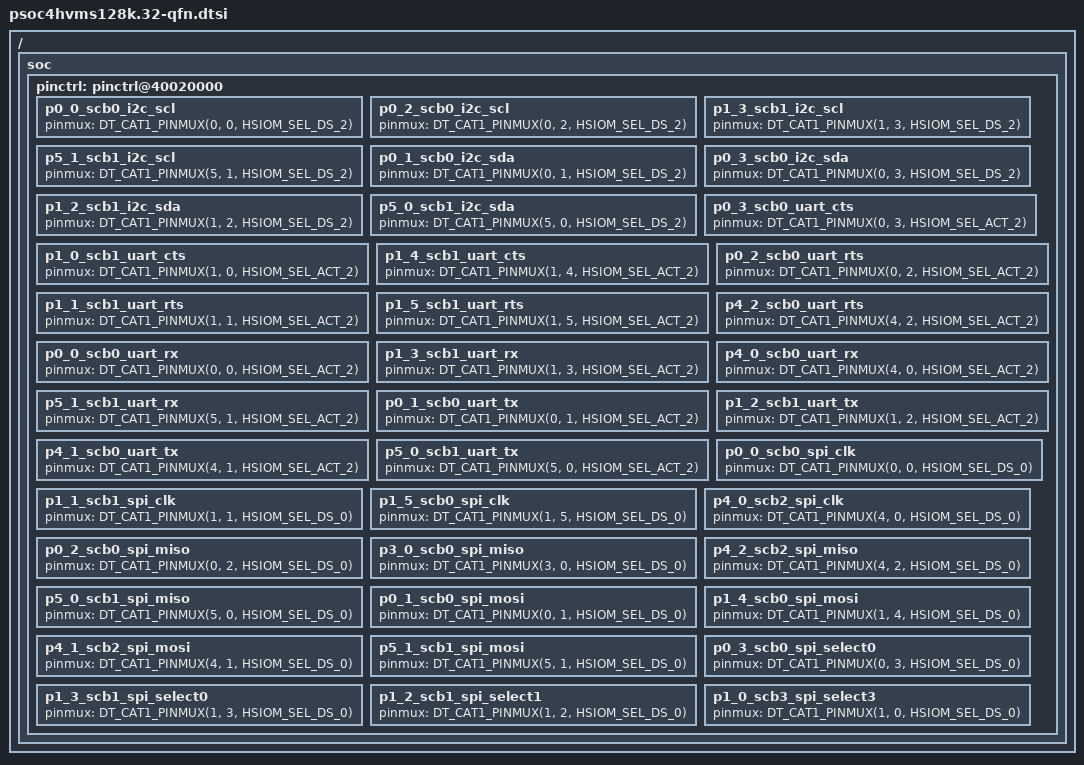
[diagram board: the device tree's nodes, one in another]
/*
 * SPDX-FileCopyrightText: Copyright (c) 2026 Infineon Technologies AG,
 * SPDX-FileCopyrightText: or an affiliate of Infineon Technologies AG. All rights reserved.
 *
 * SPDX-License-Identifier: Apache-2.0
 */

#include <zephyr/dt-bindings/gpio/gpio.h>
#include <zephyr/dt-bindings/pinctrl/ifx_cat1-pinctrl.h>
#include "psoc4hvms128k.dtsi"

/ {
	soc {
		pinctrl: pinctrl@40020000 {
			/* scb_i2c_scl */
			/omit-if-no-ref/ p0_0_scb0_i2c_scl: p0_0_scb0_i2c_scl {
				pinmux = <DT_CAT1_PINMUX(0, 0, HSIOM_SEL_DS_2)>;
			};

			/omit-if-no-ref/ p0_2_scb0_i2c_scl: p0_2_scb0_i2c_scl {
				pinmux = <DT_CAT1_PINMUX(0, 2, HSIOM_SEL_DS_2)>;
			};

			/omit-if-no-ref/ p1_3_scb1_i2c_scl: p1_3_scb1_i2c_scl {
				pinmux = <DT_CAT1_PINMUX(1, 3, HSIOM_SEL_DS_2)>;
			};

			/omit-if-no-ref/ p5_1_scb1_i2c_scl: p5_1_scb1_i2c_scl {
				pinmux = <DT_CAT1_PINMUX(5, 1, HSIOM_SEL_DS_2)>;
			};

			/* scb_i2c_sda */
			/omit-if-no-ref/ p0_1_scb0_i2c_sda: p0_1_scb0_i2c_sda {
				pinmux = <DT_CAT1_PINMUX(0, 1, HSIOM_SEL_DS_2)>;
			};

			/omit-if-no-ref/ p0_3_scb0_i2c_sda: p0_3_scb0_i2c_sda {
				pinmux = <DT_CAT1_PINMUX(0, 3, HSIOM_SEL_DS_2)>;
			};

			/omit-if-no-ref/ p1_2_scb1_i2c_sda: p1_2_scb1_i2c_sda {
				pinmux = <DT_CAT1_PINMUX(1, 2, HSIOM_SEL_DS_2)>;
			};

			/omit-if-no-ref/ p5_0_scb1_i2c_sda: p5_0_scb1_i2c_sda {
				pinmux = <DT_CAT1_PINMUX(5, 0, HSIOM_SEL_DS_2)>;
			};

			/* scb_uart_cts */
			/omit-if-no-ref/ p0_3_scb0_uart_cts: p0_3_scb0_uart_cts {
				pinmux = <DT_CAT1_PINMUX(0, 3, HSIOM_SEL_ACT_2)>;
			};

			/omit-if-no-ref/ p1_0_scb1_uart_cts: p1_0_scb1_uart_cts {
				pinmux = <DT_CAT1_PINMUX(1, 0, HSIOM_SEL_ACT_2)>;
			};

			/omit-if-no-ref/ p1_4_scb1_uart_cts: p1_4_scb1_uart_cts {
				pinmux = <DT_CAT1_PINMUX(1, 4, HSIOM_SEL_ACT_2)>;
			};

			/* scb_uart_rts */
			/omit-if-no-ref/ p0_2_scb0_uart_rts: p0_2_scb0_uart_rts {
				pinmux = <DT_CAT1_PINMUX(0, 2, HSIOM_SEL_ACT_2)>;
			};

			/omit-if-no-ref/ p1_1_scb1_uart_rts: p1_1_scb1_uart_rts {
				pinmux = <DT_CAT1_PINMUX(1, 1, HSIOM_SEL_ACT_2)>;
			};

			/omit-if-no-ref/ p1_5_scb1_uart_rts: p1_5_scb1_uart_rts {
				pinmux = <DT_CAT1_PINMUX(1, 5, HSIOM_SEL_ACT_2)>;
			};

			/omit-if-no-ref/ p4_2_scb0_uart_rts: p4_2_scb0_uart_rts {
				pinmux = <DT_CAT1_PINMUX(4, 2, HSIOM_SEL_ACT_2)>;
			};

			/* scb_uart_rx */
			/omit-if-no-ref/ p0_0_scb0_uart_rx: p0_0_scb0_uart_rx {
				pinmux = <DT_CAT1_PINMUX(0, 0, HSIOM_SEL_ACT_2)>;
			};

			/omit-if-no-ref/ p1_3_scb1_uart_rx: p1_3_scb1_uart_rx {
				pinmux = <DT_CAT1_PINMUX(1, 3, HSIOM_SEL_ACT_2)>;
			};

			/omit-if-no-ref/ p4_0_scb0_uart_rx: p4_0_scb0_uart_rx {
				pinmux = <DT_CAT1_PINMUX(4, 0, HSIOM_SEL_ACT_2)>;
			};

			/omit-if-no-ref/ p5_1_scb1_uart_rx: p5_1_scb1_uart_rx {
				pinmux = <DT_CAT1_PINMUX(5, 1, HSIOM_SEL_ACT_2)>;
			};

			/* scb_uart_tx */
			/omit-if-no-ref/ p0_1_scb0_uart_tx: p0_1_scb0_uart_tx {
				pinmux = <DT_CAT1_PINMUX(0, 1, HSIOM_SEL_ACT_2)>;
			};

			/omit-if-no-ref/ p1_2_scb1_uart_tx: p1_2_scb1_uart_tx {
				pinmux = <DT_CAT1_PINMUX(1, 2, HSIOM_SEL_ACT_2)>;
			};

			/omit-if-no-ref/ p4_1_scb0_uart_tx: p4_1_scb0_uart_tx {
				pinmux = <DT_CAT1_PINMUX(4, 1, HSIOM_SEL_ACT_2)>;
			};

			/omit-if-no-ref/ p5_0_scb1_uart_tx: p5_0_scb1_uart_tx {
				pinmux = <DT_CAT1_PINMUX(5, 0, HSIOM_SEL_ACT_2)>;
			};

			/* scb_spi_clk */
			/omit-if-no-ref/ p0_0_scb0_spi_clk: p0_0_scb0_spi_clk {
				pinmux = <DT_CAT1_PINMUX(0, 0, HSIOM_SEL_DS_0)>;
			};

			/omit-if-no-ref/ p1_1_scb1_spi_clk: p1_1_scb1_spi_clk {
				pinmux = <DT_CAT1_PINMUX(1, 1, HSIOM_SEL_DS_0)>;
			};

			/omit-if-no-ref/ p1_5_scb0_spi_clk: p1_5_scb0_spi_clk {
				pinmux = <DT_CAT1_PINMUX(1, 5, HSIOM_SEL_DS_0)>;
			};

			/omit-if-no-ref/ p4_0_scb2_spi_clk: p4_0_scb2_spi_clk {
				pinmux = <DT_CAT1_PINMUX(4, 0, HSIOM_SEL_DS_0)>;
			};

			/* scb_spi_miso */
			/omit-if-no-ref/ p0_2_scb0_spi_miso: p0_2_scb0_spi_miso {
				pinmux = <DT_CAT1_PINMUX(0, 2, HSIOM_SEL_DS_0)>;
			};

			/omit-if-no-ref/ p3_0_scb0_spi_miso: p3_0_scb0_spi_miso {
				pinmux = <DT_CAT1_PINMUX(3, 0, HSIOM_SEL_DS_0)>;
			};

			/omit-if-no-ref/ p4_2_scb2_spi_miso: p4_2_scb2_spi_miso {
				pinmux = <DT_CAT1_PINMUX(4, 2, HSIOM_SEL_DS_0)>;
			};

			/omit-if-no-ref/ p5_0_scb1_spi_miso: p5_0_scb1_spi_miso {
				pinmux = <DT_CAT1_PINMUX(5, 0, HSIOM_SEL_DS_0)>;
			};

			/* scb_spi_mosi */
			/omit-if-no-ref/ p0_1_scb0_spi_mosi: p0_1_scb0_spi_mosi {
				pinmux = <DT_CAT1_PINMUX(0, 1, HSIOM_SEL_DS_0)>;
			};

			/omit-if-no-ref/ p1_4_scb0_spi_mosi: p1_4_scb0_spi_mosi {
				pinmux = <DT_CAT1_PINMUX(1, 4, HSIOM_SEL_DS_0)>;
			};

			/omit-if-no-ref/ p4_1_scb2_spi_mosi: p4_1_scb2_spi_mosi {
				pinmux = <DT_CAT1_PINMUX(4, 1, HSIOM_SEL_DS_0)>;
			};

			/omit-if-no-ref/ p5_1_scb1_spi_mosi: p5_1_scb1_spi_mosi {
				pinmux = <DT_CAT1_PINMUX(5, 1, HSIOM_SEL_DS_0)>;
			};

			/* scb_spi_select0 */
			/omit-if-no-ref/ p0_3_scb0_spi_select0: p0_3_scb0_spi_select0 {
				pinmux = <DT_CAT1_PINMUX(0, 3, HSIOM_SEL_DS_0)>;
			};

			/omit-if-no-ref/ p1_3_scb1_spi_select0: p1_3_scb1_spi_select0 {
				pinmux = <DT_CAT1_PINMUX(1, 3, HSIOM_SEL_DS_0)>;
			};

			/* scb_spi_select1 */
			/omit-if-no-ref/ p1_2_scb1_spi_select1: p1_2_scb1_spi_select1 {
				pinmux = <DT_CAT1_PINMUX(1, 2, HSIOM_SEL_DS_0)>;
			};

			/* scb_spi_select3 */
			/omit-if-no-ref/ p1_0_scb3_spi_select3: p1_0_scb3_spi_select3 {
				pinmux = <DT_CAT1_PINMUX(1, 0, HSIOM_SEL_DS_0)>;
			};
		};
	};
};
